VERSION ""

NS_ :

BS_:
BU_: OBC
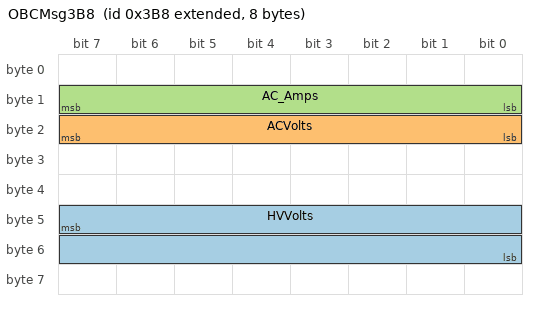
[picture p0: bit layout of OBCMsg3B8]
BO_ 2147484600 OBCMsg3B8: 8 OBC
   SG_ HVVolts : 47|16@0+ (0.02,0) [0|1000] "Volts" Vector__XXX
   SG_ ACVolts : 23|8@0+ (2,0) [0|255] "Volts" Vector__XXX
   SG_ AC_Amps : 15|8@0+ (0.2,0) [0|35] "" Vector__XXX

BA_DEF_ BO_ "GenMsgBackgroundColor" STRING ;
BA_DEF_ BO_ "GenMsgForegroundColor" STRING ;
BA_DEF_ BO_ "filterlabeling" INT 0 0;
BA_DEF_DEF_ "GenMsgBackgroundColor" "#ffffff";
BA_DEF_DEF_ "GenMsgForegroundColor" "#000000";
BA_DEF_DEF_ "filterlabeling" 1;
